# ETHCAT register map
Registers are 8-bit, read-only, no defined reset value unless marked. A register's access mark holds for its fields unless they carry their own. Addresses are absolute; registers are grouped by the start of their names; [hi:lo] are bit positions; {n}, {i} and the like mark numbered series.

## WDC
0x44010442 WDC_DATA
  [7:0] WDCNTPD
0x44010443 WDC_PDI
  [7:0] WDCNTPDI

## EEP
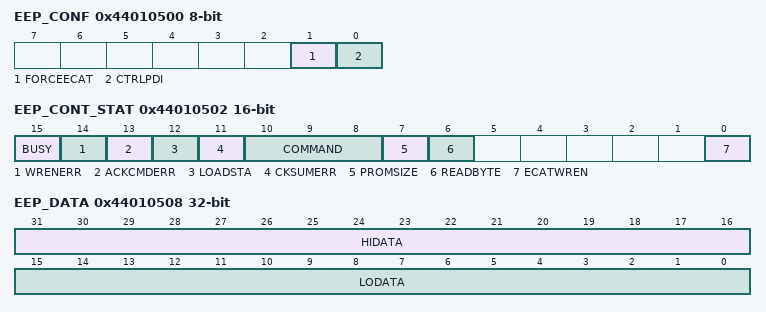
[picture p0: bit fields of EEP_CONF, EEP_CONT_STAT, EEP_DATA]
0x44010500 EEP_CONF
  [1] FORCEECAT, [0] CTRLPDI
0x44010501 EEP_STATE access not given
  [0] PDIACCEES
0x44010502 EEP_CONT_STAT 16-bit access not given
  [15] BUSY ro, [14] WRENERR ro, [13] ACKCMDERR ro, [12] LOADSTA ro, [11] CKSUMERR ro, [10:8] COMMAND, [7] PROMSIZE ro, [6] READBYTE ro, [0] ECATWREN ro
0x44010504 EEP_ADR 32-bit access not given
  [31:0] ADDRESS
0x44010508 EEP_DATA 32-bit access not given
  [31:16] HIDATA ro, [15:0] LODATA

## MII
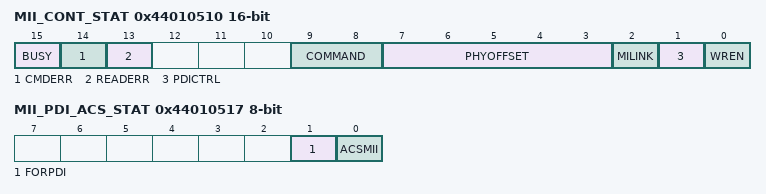
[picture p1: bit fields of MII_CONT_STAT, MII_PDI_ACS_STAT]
0x44010510 MII_CONT_STAT 16-bit access not given
  [15] BUSY ro, [14] CMDERR ro, [13] READERR, [9:8] COMMAND, [7:3] PHYOFFSET ro, [2] MILINK ro, [1] PDICTRL ro, [0] WREN ro
0x44010516 MII_ECAT_ACS_STAT
  [0] ACSMII
0x44010517 MII_PDI_ACS_STAT access not given
  [1] FORPDI ro, [0] ACSMII

## PHY
0x44010512 PHY_ADR access not given
  [4:0] PHYADDR
0x44010513 PHY_REG_ADR access not given
  [4:0] PHYREGADDR
0x44010514 PHY_DATA 16-bit access not given
  [15:0] PHYREGDATA
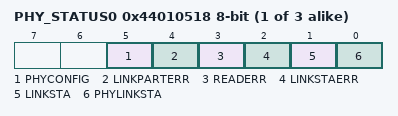
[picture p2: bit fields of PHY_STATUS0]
{0x44010518+i} PHY_STATUS{i} access not given (i=0..2)
  [5] PHYCONFIG, [4] LINKPARTERR ro, [3] READERR, [2] LINKSTAERR ro, [1] LINKSTA ro, [0] PHYLINKSTA ro

## FMMU0
0x44010600 FMMU0_L_START_ADR 32-bit
  [31:0] LSTAADR
0x44010604 FMMU0_LEN 16-bit
  [15:0] FMMULEN
0x44010606 FMMU0_L_START_BIT
  [2:0] LSTABIT
0x44010607 FMMU0_L_STOP_BIT
  [2:0] LSTPBIT
0x44010608 FMMU0_P_START_ADR 16-bit
  [15:0] PHYSTAADR
0x4401060A FMMU0_P_START_BIT
  [2:0] PHYSTABIT
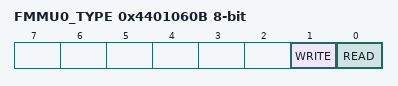
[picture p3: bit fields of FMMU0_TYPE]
0x4401060B FMMU0_TYPE
  [1] WRITE, [0] READ
0x4401060C FMMU0_ACT
  [0] ACTIVATE

## FMMU1
0x44010610 FMMU1_L_START_ADR 32-bit
  [31:0] LSTAADR
0x44010614 FMMU1_LEN 16-bit
  [15:0] FMMULEN
0x44010616 FMMU1_L_START_BIT
  [2:0] LSTABIT
0x44010617 FMMU1_L_STOP_BIT
  [2:0] LSTPBIT
0x44010618 FMMU1_P_START_ADR 16-bit
  [15:0] PHYSTAADR
0x4401061A FMMU1_P_START_BIT
  [2:0] PHYSTABIT
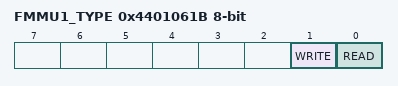
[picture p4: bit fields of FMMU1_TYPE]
0x4401061B FMMU1_TYPE
  [1] WRITE, [0] READ
0x4401061C FMMU1_ACT
  [0] ACTIVATE

## FMMU2
0x44010620 FMMU2_L_START_ADR 32-bit
  [31:0] LSTAADR
0x44010624 FMMU2_LEN 16-bit
  [15:0] FMMULEN
0x44010626 FMMU2_L_START_BIT
  [2:0] LSTABIT
0x44010627 FMMU2_L_STOP_BIT
  [2:0] LSTPBIT
0x44010628 FMMU2_P_START_ADR 16-bit
  [15:0] PHYSTAADR
0x4401062A FMMU2_P_START_BIT
  [2:0] PHYSTABIT
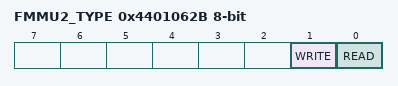
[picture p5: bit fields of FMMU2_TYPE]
0x4401062B FMMU2_TYPE
  [1] WRITE, [0] READ
0x4401062C FMMU2_ACT
  [0] ACTIVATE

## FMMU3
0x44010630 FMMU3_L_START_ADR 32-bit
  [31:0] LSTAADR
0x44010634 FMMU3_LEN 16-bit
  [15:0] FMMULEN
0x44010636 FMMU3_L_START_BIT
  [2:0] LSTABIT
0x44010637 FMMU3_L_STOP_BIT
  [2:0] LSTPBIT
0x44010638 FMMU3_P_START_ADR 16-bit
  [15:0] PHYSTAADR
0x4401063A FMMU3_P_START_BIT
  [2:0] PHYSTABIT
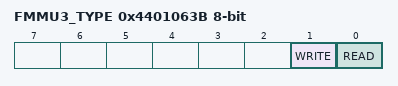
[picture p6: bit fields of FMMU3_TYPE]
0x4401063B FMMU3_TYPE
  [1] WRITE, [0] READ
0x4401063C FMMU3_ACT
  [0] ACTIVATE

## FMMU4
0x44010640 FMMU4_L_START_ADR 32-bit
  [31:0] LSTAADR
0x44010644 FMMU4_LEN 16-bit
  [15:0] FMMULEN
0x44010646 FMMU4_L_START_BIT
  [2:0] LSTABIT
0x44010647 FMMU4_L_STOP_BIT
  [2:0] LSTPBIT
0x44010648 FMMU4_P_START_ADR 16-bit
  [15:0] PHYSTAADR
0x4401064A FMMU4_P_START_BIT
  [2:0] PHYSTABIT
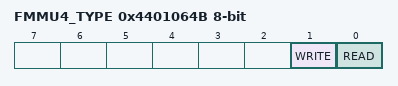
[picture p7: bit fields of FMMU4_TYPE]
0x4401064B FMMU4_TYPE
  [1] WRITE, [0] READ
0x4401064C FMMU4_ACT
  [0] ACTIVATE

## FMMU5
0x44010650 FMMU5_L_START_ADR 32-bit
  [31:0] LSTAADR
0x44010654 FMMU5_LEN 16-bit
  [15:0] FMMULEN
0x44010656 FMMU5_L_START_BIT
  [2:0] LSTABIT
0x44010657 FMMU5_L_STOP_BIT
  [2:0] LSTPBIT
0x44010658 FMMU5_P_START_ADR 16-bit
  [15:0] PHYSTAADR
0x4401065A FMMU5_P_START_BIT
  [2:0] PHYSTABIT
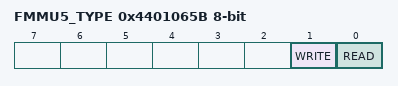
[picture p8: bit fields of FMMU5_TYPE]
0x4401065B FMMU5_TYPE
  [1] WRITE, [0] READ
0x4401065C FMMU5_ACT
  [0] ACTIVATE
